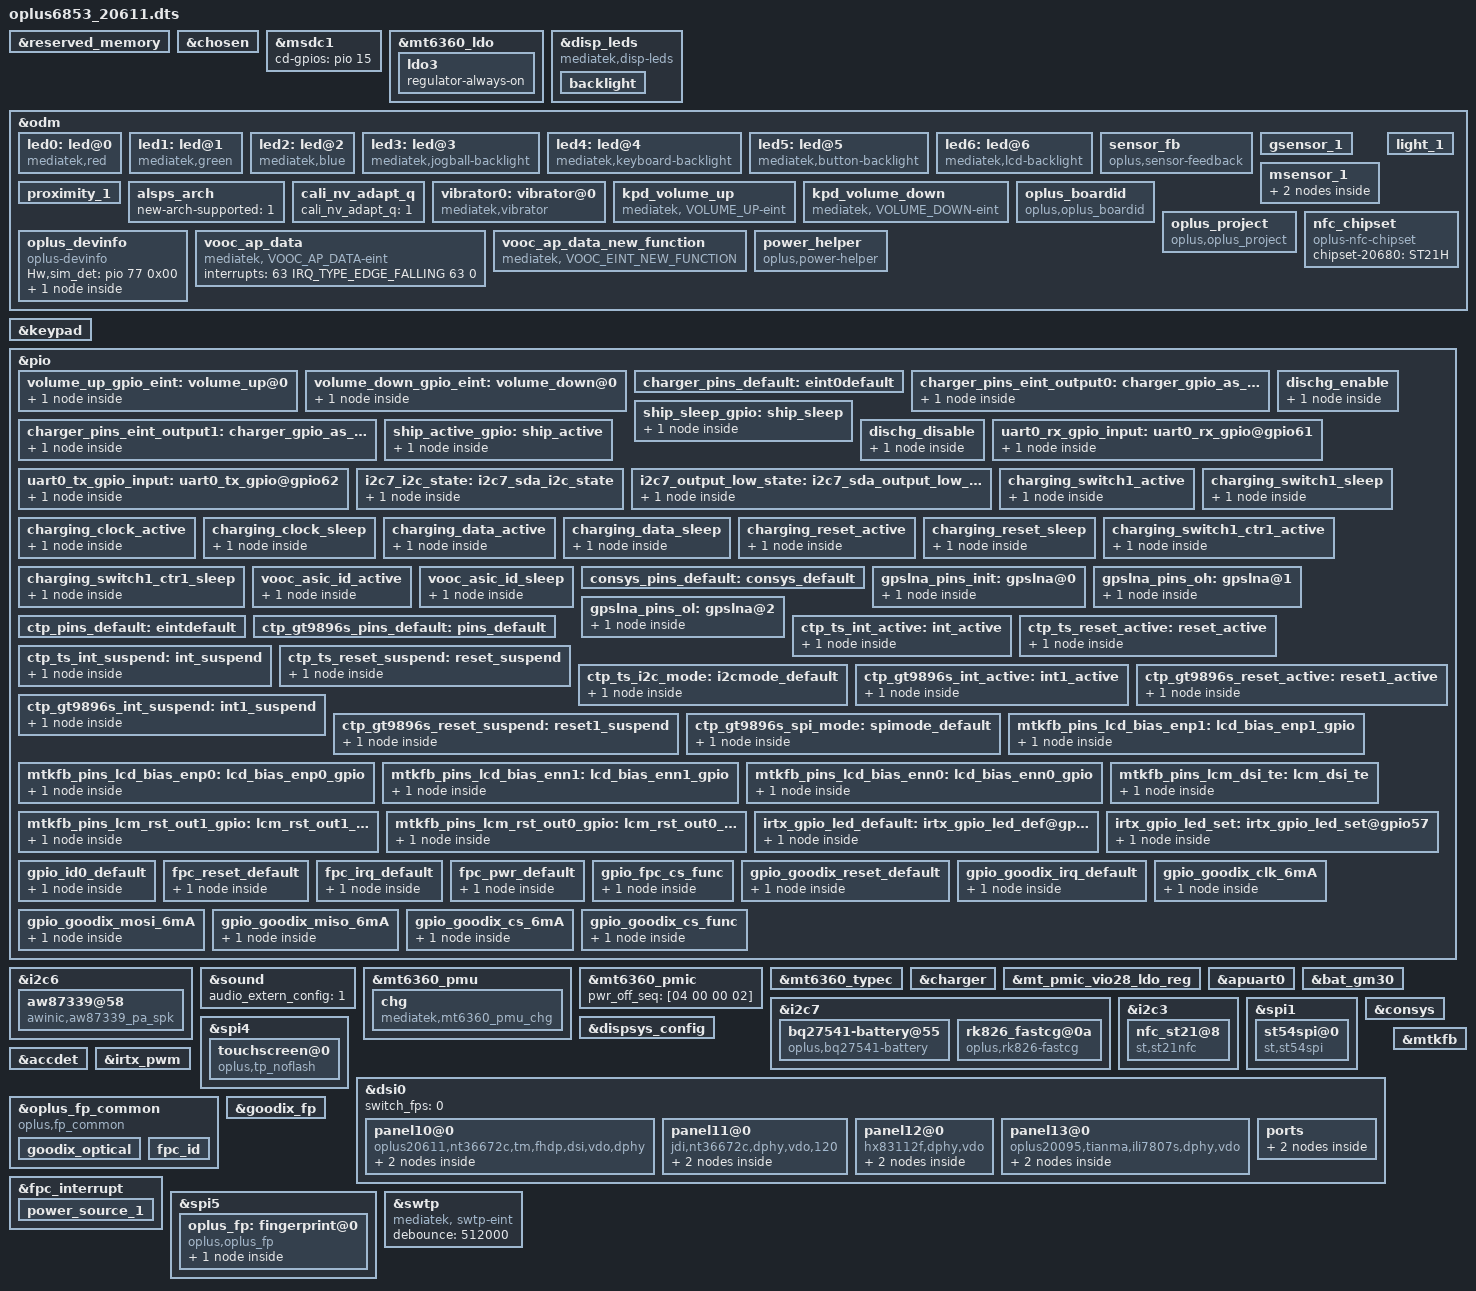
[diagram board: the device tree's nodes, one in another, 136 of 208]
/*
 * Mediatek's mt6853 SoC device tree source
 *
 * Copyright (C) 2016 MediaTek Inc.
 *
 * This program is free software; you can redistribute it and/or modify
 * it under the terms of the GNU General Public License version 2 as
 * published by the Free Software Foundation.
 *
 * This program is distributed in the hope that it will be useful,
 * but WITHOUT ANY WARRANTY; without even the implied warranty of
 * MERCHANTABILITY or FITNESS FOR A PARTICULAR PURPOSE.
 * See http://www.gnu.org/licenses/gpl-2.0.html for more details.
 */
/dts-v1/;
/plugin/;
#include <dt-bindings/interrupt-controller/irq.h>
#include <dt-bindings/interrupt-controller/arm-gic.h>
#include <dt-bindings/pinctrl/mt6853-pinfunc.h>

&reserved_memory {
};

/* chosen */
&chosen {

	atag,videolfb-fb_base_l = <0x7e605000>;
	atag,videolfb-fb_base_h = <0x0>;
	atag,videolfb-islcmfound = <1>;
	atag,videolfb-islcm_inited = <0>;
	atag,videolfb-fps= <6000>;
	atag,videolfb-vramSize= <0x1be0000>;
	atag,videolfb-lcmname=
		"nt35595_fhd_dsi_cmd_truly_nt50358_drv";
};
&msdc1 {
	cd-gpios = <&pio 15 0>;
	status = "okay";
};
&mt6360_ldo {
	sdcard_det_en = <1>;
	sdcard_hlact = <0>;
};

&disp_leds {
	compatible = "mediatek,disp-leds";

	backlight {
		label = "lcd-backlight";
		max-brightness = <4095>;
		led-bits = <12>;
		trans-bits = <12>;
		default-state = "on";
	};
};

&odm {
	led0:led@0 {
		compatible = "mediatek,red";
		led_mode = <0>;
		data = <1>;
		pwm_config = <0 0 0 0 0>;
	};
	led1:led@1 {
		compatible = "mediatek,green";
		led_mode = <0>;
		data = <1>;
		pwm_config = <0 0 0 0 0>;
	};
	led2:led@2 {
		compatible = "mediatek,blue";
		led_mode = <0>;
		data = <1>;
		pwm_config = <0 0 0 0 0>;
	};
	led3:led@3 {
		compatible = "mediatek,jogball-backlight";
		led_mode = <0>;
		data = <1>;
		pwm_config = <0 0 0 0 0>;
	};
	led4:led@4 {
		compatible = "mediatek,keyboard-backlight";
		led_mode = <0>;
		data = <1>;
		pwm_config = <0 0 0 0 0>;
	};
	led5:led@5 {
		compatible = "mediatek,button-backlight";
		led_mode = <0>;
		data = <1>;
		pwm_config = <0 0 0 0 0>;
	};
	led6:led@6 {
		compatible = "mediatek,lcd-backlight";
		led_mode = <4>;
		data = <1>;
		pwm_config = <0 1 0 0 0>;
	};

	sensor_fb: sensor_fb {
		compatible = "oplus,sensor-feedback";
	};

		/*
	enum {
		LIS3DH,
		LSM6DS3,
		BMI160,
		LIS2HH12,
		LSM6DSM,
		BMI2XY,
	};
	*/

	gsensor_1: gsensor_1 {
		status = "okay";
		sensor_name = <4>;//LSM6DSM
		i2c_num = <2>;
		i2c_addr = <0>;
		direction = <3>;
		eint_num = <3>;
		gyro_cali_version= <2>;
		acc_cali_range= <200 200 200>; //250mg
		step_count_7_en = <0>;
		config_miso = <0>;
		correct_y_bias = <0>;
                cali_nv_adapt_q_flag = <1>; // just for oplus MTK5G q projects
	};
	/*
	enum {
		AKM09911,
		MMC3530,
		MMC5603,
		MXG4300,
	};
	*/
	msensor_1: msensor_1 {
		status = "okay";
		sensor_name = <2>;//MMC5603
		i2c_num = <0>;
		i2c_addr = <48>;
		direction = <2>;
		eint_num = <0>;
 		parameter-number= <18>;
                para_num = <2>;
		mag_para_1 {
			match_projects = <20611 20610 20613 20686>;
			soft-mag-parameter = <9998 0 109 1 199 0 107 0 8922 0 268 0 58 1 468 0 10857 0>;
		};
		mag_para_2 {
			match_projects = <20680>;
			soft-mag-parameter = <15500 0 780 0 73 0 1639 0 9540 0 436 0 2000 0 5010 1 12560 0>;
		};
	};
	/*
	enum {
		TMD2725,
		APSD9922,
		STK3335,
		STK3331,
		STK2232,
		TCS3701,
		STK32600,
		TCS3408,
		STK33502,
	};
	*/
	proximity_1: proximity_1 {
		status = "okay";
		sensor_name = <7>;//STK33502
		i2c_num = <0>;
		i2c_addr = <70>;
		direction = <4>;
		eint_num = <11>;
		low_step = <300>;
		high_step = <400>;
		low_limit = <400>;
		high_limit = <600>;
		dirty_low_step = <100>;
		dirty_high_step = <150>;
		ps_dirty_limit = <1023>;
		ps_ir_limit = <500>;
		ps_adjust_min = <0>;
		ps_adjust_max = <600>;
		sampling_count = <5>;
		step_max = <400>;
		step_min = <100>;
		step_div = <1500>;
		anti_shake_delta = <80>;
		dynamic_cali_max = <2000>;
		raw2offset_radio = <1000>;
		offset_max = <60000>;
		offset_range_min = <0>;
		offset_range_max = <65534>;
		force_cali_limit = <2000>;
		cali_jitter_limit = <30>;
		cal_offset_margin = <3000>;
	};
	light_1: light_1 {
		status = "okay";
		sensor_name = <7>;//STK33502
		i2c_num = <0>;
		i2c_addr = <70>;
		direction = <4>;
		eint_num = <11>;
		als_buffer_length =<4>;
		als_type = <1>;//<1-normal;2-under screen;3-normal needed compensation>
		als_ratio = <170>;
		device_name = "stk33502";
		coefficient_mode = <1>;
	};
	alsps_arch: alsps_arch {
		status = "okay";
		new-arch-supported = <1>;
	};
	cali_nv_adapt_q: cali_nv_adapt_q {
		status = "okay";
		cali_nv_adapt_q = <1>;
	};
	vibrator0:vibrator@0 {
		compatible = "mediatek,vibrator";
		vib_timer = <30>;
		vib_limit = <0>;
		vib_vol= <11>;
	};

	kpd_volume_up:kpd_volume_up {
		compatible = "mediatek, VOLUME_UP-eint";
		interrupt-parent = <&pio>;
		interrupts = <1 IRQ_TYPE_EDGE_FALLING 1 0>;
		debounce = <32000>;
		status = "okay";
	};

	kpd_volume_down:kpd_volume_down {
		compatible = "mediatek, VOLUME_DOWN-eint";
		interrupt-parent = <&pio>;
		interrupts = <80 IRQ_TYPE_EDGE_FALLING 80 0>;
		debounce = <32000>;
		status = "okay";
	};
	oplus_boardid:oplus_boardid {
		compatible = "oplus,oplus_boardid";
		oplus_boardid,dtsino="20611";//only one u32
		oplus_boardid,pcbmask="0xffff";//all mask 0xffff
	};

	oplus_project:oplus_project {
		compatible = "oplus,oplus_project";
	};
	oplus_devinfo:oplus_devinfo {
		compatible = "oplus-devinfo";

		main-sub {
			compatible = "hw-match, main-sub";
			aboard-patterns = <0 0 0 0 0 0>;
			/*main board*/
			match-projects = <20610 20611 20613 20680 20686 20095>;
		};
	};

	vooc_ap_data:vooc_ap_data {
		compatible = "mediatek, VOOC_AP_DATA-eint";
		interrupts = <63 IRQ_TYPE_EDGE_FALLING 63 0>;
	};
	vooc_ap_data_new_function:vooc_ap_data_new_function {
		compatible = "mediatek, VOOC_EINT_NEW_FUNCTION";
	};

	//#ifdef OPLUS_FEATURE_NFC_CONSOFT
        nfc_chipset:nfc_chipset {
                compatible = "oplus-nfc-chipset";
                chipset-20680 = "ST21H";
        };
	//#endif /* OPLUS_FEATURE_NFC_CONSOFT */
};

&oplus_devinfo {
	Hw,sim_det = <&pio 77 0x00>;
};

&keypad {
	keypad,volume-up	= <&pio 1 0x00>;
	keypad,volume-down	= <&pio 80 0x00>;
	pinctrl-names = "volume_up_as_int", "volume_down_as_int";
	pinctrl-0 = <&volume_up_gpio_eint>;
	pinctrl-1 = <&volume_down_gpio_eint>;
	status = "okay";
};
&pio {
	volume_up_gpio_eint:volume_up@0{
		pins_cmd_dat {
			pinmux = <PINMUX_GPIO1__FUNC_GPIO1>;
			slew-rate = <0>;  /*direction 0:in, 1:out*/
			input-enable;
		};
	};

	volume_down_gpio_eint:volume_down@0{
		pins_cmd_dat {
			pinmux = <PINMUX_GPIO80__FUNC_GPIO80>;
			slew-rate = <0>;  /*direction 0:in, 1:out*/
			input-enable;
		};
	};
};

&i2c6 {
    #address-cells = <1>;
    #size-cells = <0>;

    aw87339@58 {
        compatible = "awinic,aw87339_pa_spk";
        reg = <0x58>;
        //reset-gpio = <&tlmm 114 0x01>;
        reset-gpio = <&pio 139 0>;
        status = "okay";
    };
};

&sound {
	/* this dtsi config for product's special config, AudioHal read ctl 'OPLUS_AUDIO_EXTERN_CONFIG'
	 * get the values*
	 * 1st value --> PA type: 0:NXP Pa, 1:Awinic Pa */
	audio_extern_config = <1>;
};


&oplus_devinfo {
	Hw,sim_det = <&pio 77 0x00>;
};

/* Charging Start */

&mt6360_pmu {
	mt6360,intr_gpio_num = <10>; /* direct defined GPIO num */
	mt6360,intr_gpio = <&pio 10 0x0>;
	disable_lpsd = <1>;
};

&mt6360_pmic {
	pwr_off_seq = [04 00 00 02];
};

&mt6360_typec {
	mt6360pd,intr_gpio_num = <9>; /* direct defined GPIO num */
	mt6360pd,intr_gpio = <&pio 9 0x0>;
	//mt6360pd,pcb_gpio = <&pio 57 0x0>;
	//mt6360pd,pcb_gpio_num = <57>;
};

&mt6360_pmu {
	chg {
		compatible = "mediatek,mt6360_pmu_chg";
		interrupt-parent = <&mt6360_pmu>;
		interrupts = <4 0>, <6 0>, <7 0>, <9 0>,
				<12 0>, <13 0>, <14 0>, <15 0>,
				<27 0>, <29 0>, <30 0>, <32 0>,
				<35 0>, <40 0>, <48 0>, <60 0>,
				<53 0>;
		interrupt-names = "chg_treg_evt", "chg_mivr_evt",
				"pwr_rdy_evt", "chg_batsysuv_evt",
				"chg_vsysuv_evt", "chg_vsysov_evt",
				"chg_vbatov_evt", "chg_vbusov_evt",
				"chg_tmri", "chg_adpbadi",
				"chg_rvpi",  "chg_aiccmeasl",
				"wdtmri", "pumpx_donei",
				"attachi", "chrdet_ext_evt",
				"hvdcp_det";
		io-channels = <&adc 0>, <&adc 1>, <&adc 3>, <&adc 4>,
				<&adc 5>, <&adc 6>, <&adc 8>, <&adc 10>;
		io-channel-names = "USBID", "VBUSDIV5", "VSYS", "VBAT",
				"IBUS", "IBAT", "TEMP_JC", "TS";
		chg_name = "primary_chg";
		ichg = <2000000>;               /* uA */
		aicr = <500000>;                /* uA */
		mivr = <4400000>;               /* uV */
		cv = <4350000>;                 /* uA */
		ieoc = <150000>;                /* uA */
		safety_timer = <12>;            /* hour */
		ircmp_resistor = <25000>;       /* uohm */
		ircmp_vclamp = <32000>;         /* uV */
		en_te = <1>;
		en_wdt = <1>;
		aicc_once = <1>;
		post_aicc = <1>;
		batoc_notify = <0>;
	};
};
&mt6360_ldo{
	ldo3{
		regulator-always-on;
	};
};
//#ifdef OPLUS_FEATURE_SDCARD
&mt6360_ldo {
	ldo5_ctrls = [00 80 01 2d a4];
};
//#endif OPLUS_FEATURE_SDCARD
&charger {
	io-channels = <&auxadc 3>,
		<&auxadc 4>,
		<&auxadc 5>;
	io-channel-names = "auxadc3-chargeric_temp",
		"auxadc4-usb_temp_v_l",
		"auxadc5-usb_temp_v_r";

	pinctrl-names = "default", "charger_gpio_as_output_low", "charger_gpio_as_output_high", "ship_sleep", "ship_active", 
		"dischg_enable", "dischg_disable";
		//"ccdetect_active","ccdetect_sleep";
	pinctrl-0 = <&charger_pins_default>;
	pinctrl-1 = <&charger_pins_eint_output0>;//USB_ON
	pinctrl-2 = <&charger_pins_eint_output1>;//USB_ON
	pinctrl-3 = <&ship_sleep_gpio>;
	pinctrl-4 = <&ship_active_gpio>;
	pinctrl-5 = <&dischg_enable>;
	pinctrl-6 = <&dischg_disable>;
	//pinctrl-5 = <&shortc_active_gpio>;
	//pinctrl-7 = <&ccdetect_active>;
	//pinctrl-8 = <&ccdetect_sleep>;

	qcom,input_current_charger_ma = <2300>;
	qcom,pd_input_current_charger_ma = <3300>;
	qcom,qc_input_current_charger_ma = <2000>;
	qcom,input_current_usb_ma = <500>;

	qcom,input_current_cdp_ma = <1500>;
	qcom,input_current_led_ma = <1200>;
	qcom,input_current_led_ma_high = <1200>;
	qcom,input_current_led_ma_warm = <1500>;
	qcom,input_current_led_ma_normal = <2300>;
	qcom,led_warm_bat_decidegc = <350>;
	qcom,led_high_bat_decidegc = <370>;

	qcom,input_current_camera_ma = <1200>;

	qcom,input_current_vooc_led_ma_high = <1200>;
	qcom,input_current_vooc_led_ma_warm = <1800>;
	qcom,input_current_vooc_led_ma_normal = <3600>;
	qcom,input_current_vooc_ma_normal = <3600>;
	qcom,vooc_temp_bat_normal_decidegc = <350>;
	qcom,input_current_vooc_ma_warm = <3200>;
	qcom,vooc_temp_bat_warm_decidegc = <370>;
	qcom,input_current_vooc_ma_high = <2200>;
	qcom,vooc_temp_bat_hot_decidegc = <440>;

	qcom,charger_current_vooc_ma_normal = <1800>;

	qcom,input_current_calling_ma = <1500>;

	qcom,overtemp_bat_decidegc = <350>;
	qcom,iterm_disabled = <0>;
	qcom,iterm_ma = <255>;
	qcom,recharge-mv = <100>;
	qcom,batt_capacity_mah = <5000>;/*typical capacity*/

	qcom,removed_bat_decidegc = <190>;  /*<-19C*/

	qcom,cold_bat_decidegc = <20>;  /*-2C~0C*/
	qcom,temp_cold_vfloat_mv = <3980>;
	qcom,temp_cold_fastchg_current_ma = <350>;

	qcom,little_cold_bat_decidegc = <0>;    /*0C~5C*/
	qcom,temp_little_cold_vfloat_mv = <4435>;
	qcom,temp_little_cold_fastchg_current_ma_high = <2300>;
	qcom,temp_little_cold_fastchg_current_ma_low = <1400>;
	qcom,temp_little_cold_fastchg_current_ma = <1400>;
	qcom,pd_temp_little_cold_fastchg_current_ma_high = <2300>;
	qcom,pd_temp_little_cold_fastchg_current_ma_low = <1400>;
	qcom,qc_temp_little_cold_fastchg_current_ma_high = <2000>;
	qcom,qc_temp_little_cold_fastchg_current_ma_low = <1400>;

	qcom,cool_bat_decidegc = <50>;  /*5C~12C*/
	qcom,temp_cool_vfloat_mv = <4435>;
	qcom,temp_cool_fastchg_current_ma_high = <2300>;
	qcom,temp_cool_fastchg_current_ma_low = <2300>;
	qcom,pd_temp_cool_fastchg_current_ma_high = <2300>;
	qcom,pd_temp_cool_fastchg_current_ma_low = <2300>;
	qcom,qc_temp_cool_fastchg_current_ma_high = <2000>;
	qcom,qc_temp_cool_fastchg_current_ma_low = <2000>;

	qcom,little_cool_bat_decidegc = <120>;  /*12C~16C*/
	qcom,temp_little_cool_vfloat_mv = <4435>;
	qcom,temp_little_cool_fastchg_current_ma = <2300>;
	qcom,pd_temp_little_cool_fastchg_current_ma = <3300>;
	qcom,qc_temp_little_cool_fastchg_current_ma = <2000>;

	qcom,normal_bat_decidegc = <160>;       /*16C~44C*/
	qcom,temp_normal_fastchg_current_ma = <2300>;
	qcom,temp_normal_vfloat_mv = <4435>;
	qcom,pd_temp_normal_fastchg_current_ma = <3300>;
	qcom,qc_temp_normal_fastchg_current_ma = <2000>;

	qcom,warm_bat_decidegc = <450>;         /*45C~53C*/ /*8pin Bat Vooc project need add 3 degree C*/
	qcom,temp_warm_vfloat_mv = <4130>;
	qcom,temp_warm_fastchg_current_ma = <1400>;
	qcom,pd_temp_warm_fastchg_current_ma = <1400>;
	qcom,qc_temp_warm_fastchg_current_ma = <1400>;
	qcom,temp_warm_fastchg_current_ma_led_on = <500>;

	qcom,hot_bat_decidegc = <530>;

	qcom,non_standard_vfloat_mv = <3980>;
	qcom,non_standard_fastchg_current_ma = <512>;

	qcom,short_c_bat_cv_mv = <4330>;
	qcom,short_c_bat_vfloat_mv = <3800>;
	qcom,short_c_bat_fastchg_current_ma = <512>;

	qcom,cold_vfloat_sw_limit = <3930>;
	qcom,little_cold_vfloat_sw_limit = <4385>;
	qcom,cool_vfloat_sw_limit = <4385>;
	qcom,little_cool_vfloat_sw_limit = <4385>;
	qcom,normal_vfloat_sw_limit = <4385>;
	qcom,warm_vfloat_sw_limit = <4080>;
	qcom,non_standard_vfloat_sw_limit = <3930>;
	qcom,short_c_bat_vfloat_sw_limit = <3750>;

	qcom,max_chg_time_sec = <72000>;
	qcom,charger_hv_thr = <5800>;
	qcom,charger_recv_thr = <5500>;
	qcom,charger_lv_thr = <3400>;
	qcom,vbatt_full_thr = <4400>;
	qcom,vbatt_hv_thr = <4550>;
	qcom,vfloat_step_mv = <8>;
	qcom,non_standard_vfloat_over_sw_limit = <3990>;
	qcom,cold_vfloat_over_sw_limit = <3990>;
	qcom,little_cold_vfloat_over_sw_limit = <4445>;
	qcom,cool_vfloat_over_sw_limit = <4445>;
	qcom,little_cool_vfloat_over_sw_limit = <4445>;
	qcom,normal_vfloat_over_sw_limit = <4445>;
	qcom,warm_vfloat_over_sw_limit = <4140>;

	qcom,vbatt_power_off = <3300>;
	qcom,vbatt_soc_1 = <3410>;
	qcom,vooc_project = <1>;
	qcom,vbatt_num = <1>;
	qcom,normal_vterm_hw_inc = <18>;
	qcom,non_normal_vterm_hw_inc = <18>;
	qcom,new_ui_warning_support;
	qcom,ffc_support;
	qcom,ff1_normal_fastchg_ma = <1500>;
	qcom,ff1_exit_step_ma = <550>;

	qcom,ff1_warm_fastchg_ma = <1500>;
	qcom,ff1_warm_exit_step_ma = <500>;

	qcom,ffc2_normal_fastchg_ma = <1200>;/*12C~35c*/
	qcom,ffc2_exit_step_ma = <250>;

	qcom,ffc2_temp_low_decidegc = <120>;
	qcom,ffc2_temp_warm_decidegc = <350>;

	qcom,ffc2_warm_fastchg_ma = <1250>;/*35C~40c*/
	qcom,ffc2_warm_exit_step_ma = <250>;/*35C~40c*/

	qcom,ffc2_temp_high_decidegc = <400>;

	qcom,ffc_normal_vfloat_sw_limit = <4475>;
	qcom,ffc_warm_vfloat_sw_limit = <4475>;

	qcom,ffc2_normal_vfloat_sw_limit = <4475>;
	qcom,ffc2_warm_vfloat_sw_limit = <4475>;

	qcom,ffc_temp_normal_vfloat_mv = <4550>;
	qcom,ffc1_temp_normal_vfloat_mv = <4550>;
	qcom,ffc2_temp_normal_vfloat_mv = <4550>;
	qcom,ffc_normal_vfloat_over_sw_limit = <4550>;
	qcom,ffc1_normal_vfloat_over_sw_limit = <4550>;
	qcom,ffc2_normal_vfloat_over_sw_limit = <4550>;


	qcom,default_iterm_ma = <255>;
	qcom,default_temp_normal_fastchg_current_ma = <2200>;
	qcom,default_normal_vfloat_sw_limit = <4385>;
	qcom,default_temp_normal_vfloat_mv = <4435>;
	qcom,default_normal_vfloat_over_sw_limit = <4445>;

	qcom,default_temp_little_cool_fastchg_current_ma = <2200>;
	qcom,default_little_cool_vfloat_sw_limit = <4385>;
	qcom,default_temp_little_cool_vfloat_mv = <4435>;
	qcom,default_little_cool_vfloat_over_sw_limit = <4445>;

	qcom,smart_charge_version = <0>;

	qcom,vooc_show_ui_soc_decimal;
	qcom,ui_soc_decimal_speedmin = <20>;//2A
	qcom,check_batt_full_by_sw;
	qcom,external_gauge;
	qcom,chg_ctrl_by_calling;
	qcom,chg_ctrl_by_lcd;
	//qcom,chg_ctrl_by_vooc;
	qcom,chg_ctrl_by_camera;
	qcom,chargerid_support;
	qcom,sw_vfloat_over_protect_enable;
	qcom,lpd-disable;
	//for PD9V or QC9V
	qcom,vbatt_pdqc_to_5v_thr = <4180>;

	//GPIO config:
	qcom,chargerid_switch-gpio = <&pio 40 0x00>;//USB_ON
	qcom,ship-gpio = <&pio 34 0x00>;
	qcom,dischg-gpio = <&pio 39 0x00>;//VBUS_SHORT
	//qcom,shortc-gpio = <&pio 121 0x00>;
	//qcom,ccdetect-gpio = <&pio 5 0x00>;//USB_ACC_INT
};
&mt_pmic_vio28_ldo_reg {
	regulator-name = "vio28";
	regulator-min-microvolt = <3000000>;
	regulator-max-microvolt = <3000000>;
	regulator-enable-ramp-delay = <240>;
};
//#endif /* VENDOR_EDIT */

&pio {
	charger_pins_default: eint0default {
	};

	charger_pins_eint_output0: charger_gpio_as_output_low {
		pins_cmd_dat {
			pinmux = <PINMUX_GPIO40__FUNC_GPIO40>;
			slew-rate = <1>;
			output-low;
		};
	};

	charger_pins_eint_output1: charger_gpio_as_output_high {
		pins_cmd_dat {
			pinmux = <PINMUX_GPIO40__FUNC_GPIO40>;
			slew-rate = <1>;
			output-high;
		};
	};

	ship_sleep_gpio: ship_sleep {
		pins_cmd_dat {
			pinmux = <PINMUX_GPIO34__FUNC_GPIO34>;
			slew-rate = <1>;
			output-low;
		};
	};

	ship_active_gpio: ship_active {
		pins_cmd_dat {
			pinmux = <PINMUX_GPIO34__FUNC_GPIO34>;
			slew-rate = <1>;
			output-high;
		};
	};
	dischg_enable: dischg_enable {
		pins_cmd_dat {
			pinmux = <PINMUX_GPIO39__FUNC_GPIO39>;
			slew-rate = <1>;//0:input direction 1:output direction
			bias-pull-up = <00>;
			output-high;
		};
	};

	dischg_disable: dischg_disable {
		pins_cmd_dat {
			pinmux = <PINMUX_GPIO39__FUNC_GPIO39>;
			slew-rate = <1>;
			bias-pull-down = <00>;
			output-low;
		};
	};
};

&apuart0 {
	pinctrl-names = "uart0_rx_gpio",
			"uart0_tx_gpio";
	pinctrl-0 = <&uart0_rx_gpio_input>;
	pinctrl-1 = <&uart0_tx_gpio_input>;
	status = "okay";
};

&pio {
	uart0_rx_gpio_input:uart0_rx_gpio@gpio61 {
		pins_cmd_dat {
			pinmux = <PINMUX_GPIO61__FUNC_GPIO61>;
			input-enable;
			slew-rate = <0>;
			//bias-disable;
			bias-pull-down = <00>;
		};
	};
	uart0_tx_gpio_input:uart0_tx_gpio@gpio62 {
		pins_cmd_dat {
			pinmux = <PINMUX_GPIO62__FUNC_GPIO62>;
			input-enable;
			slew-rate = <0>;
			//bias-disable;
			bias-pull-down = <00>;
		};
	};
};

//#endif /* VENDOR_EDIT */




&bat_gm30 {
	DISABLE_MTKBATTERY = <(1)>;
	enable_tmp_intr_suspend = <(1)>;
};

&i2c7 {
       pinctrl-names = "i2c-state", "output-low-state";

       pinctrl-0 = <&i2c7_i2c_state>;
       pinctrl-1 = <&i2c7_output_low_state>;
};
&pio {
       i2c7_i2c_state: i2c7_sda_i2c_state {
                pins_cmd_dat {
                          pinmux = <PINMUX_GPIO112__FUNC_SDA7>;
                          slew-rate = <0>;
                          bias-pull-up = <11>;
                };
       };
       i2c7_output_low_state: i2c7_sda_output_low_state {
                pins_cmd_dat {
                          pinmux = <PINMUX_GPIO112__FUNC_GPIO112>;
                          slew-rate = <1>;
                          output-low;
                };
       };
};
&i2c7 {
	status = "okay";
	//clock-frequency = <100000>;
	bq27541-battery@55 {
		status = "okay";
		compatible = "oplus,bq27541-battery";
		reg = <0x55 0>;
		qcom,modify-soc-smooth;
		//qcom,batt_bq28z610;
                //qcom,bq28z610_need_balancing;
	};


	rk826_fastcg@0a{
		status = "okay";
		compatible = "oplus,rk826-fastcg";
		reg = <0x0a 0>;
		qcom,vooc-low-temp = <50>;
		qcom,oplus_batt_4400mv;
		qcom,vooc_fw_update_newmethod;
		qcom,vooc-high-temp = <430>;
		qcom,vooc-low-soc = <1>;
		qcom,vooc-high-soc = <85>;
		qcom,vooc-fw-type = <7>;

		qcom,vooc_cool_bat_volt = <3450>;
		qcom,vooc_little_cool_bat_volt = <3400>;
		qcom,vooc_normal_bat_volt = <3350>;
		qcom,vooc_warm_bat_volt = <3300>;

		qcom,vooc_cool_bat_suspend_volt = <3450>;
		qcom,vooc_little_cool_bat_suspend_volt = <3400>;
		qcom,vooc_normal_bat_suspend_volt = <3350>;
		qcom,vooc_warm_bat_suspend_volt = <3300>;

		qcom,vooc_multistep_adjust_current_support;
		qcom,vooc_multistep_initial_batt_temp = <1000>;
		qcom,vooc_strategy_normal_current = <0x06>;

		qcom,vooc-normal-to-little-cool-current = <0x04>;
		//qcom,vooc_batt_over_high_temp = <440>;//exit move to fastchg bin
		//qcom,vooc_batt_over_low_temp = <45>;//exit move to fastchg bin
		qcom,vooc_over_high_or_low_current = <0x02>;

		qcom,vooc_strategy1_batt_high_temp0 = <410>;
		qcom,vooc_strategy1_batt_high_temp1 = <425>;
		qcom,vooc_strategy1_batt_high_temp2 = <435>;
		qcom,vooc_strategy1_batt_low_temp2 = <430>;
		qcom,vooc_strategy1_batt_low_temp1 = <410>;
		qcom,vooc_strategy1_batt_low_temp0 = <390>;

		qcom,vooc_strategy1_high_current0 = <0x04>;//4A
		qcom,vooc_strategy1_high_current1 = <0x03>;//3A
		qcom,vooc_strategy1_high_current2 = <0x02>;//2A
		qcom,vooc_strategy1_low_current2 = <0x03>;//3A
		qcom,vooc_strategy1_low_current1 = <0x05>;//5A
		qcom,vooc_strategy1_low_current0 = <0x06>;//6A

		qcom,vooc_strategy2_batt_up_temp1 = <375>;
		qcom,vooc_strategy2_batt_up_down_temp2 = <380>;
		qcom,vooc_strategy2_batt_up_temp3 = <390>;
		qcom,vooc_strategy2_batt_up_down_temp4 = <400>;
		qcom,vooc_strategy2_batt_up_temp5 = <410>;
		qcom,vooc_strategy2_batt_up_temp6 = <415>;
		qcom,vooc_strategy2_high0_current = <0x06>;
		qcom,vooc_strategy2_high1_current = <0x06>;
		qcom,vooc_strategy2_high2_current = <0x06>;
		qcom,vooc_strategy2_high3_current = <0x06>;
		pinctrl-names = "switch1_act_switch2_act", "switch1_sleep_switch2_sleep",
						"switch1_act_switch3_act", "switch1_sleep_switch3_sleep",
						"switch1_act_switch2_sleep", "switch1_sleep_switch2_act",
						"clock_active","clock_sleep",
						"data_active","data_sleep",
						"reset_active","reset_sleep",
						"charging_switch1_ctr1_active","charging_switch1_ctr1_sleep",
						"vooc_asic_id_active","vooc_asic_id_sleep";
		pinctrl-0 = <&charging_switch1_active>;//USB_SW_CTRL1
		pinctrl-1 = <&charging_switch1_sleep>;//USB_SW_CTRL1
		pinctrl-2 = <&charging_switch1_active>;//USB_SW_CTRL1
		pinctrl-3 = <&charging_switch1_sleep>;//USB_SW_CTRL1
		pinctrl-4 = <&charging_switch1_active>;//USB_SW_CTRL1
		pinctrl-5 = <&charging_switch1_sleep>;//USB_SW_CTRL1
		pinctrl-6 = <&charging_clock_active>;//AP_CLK
		pinctrl-7 = <&charging_clock_sleep>;//AP_CLK
		pinctrl-8 = <&charging_data_active>;//AP_DATA
		pinctrl-9 = <&charging_data_sleep>;//AP_DATA
		pinctrl-10 = <&charging_reset_active>;//MCU_EN
		pinctrl-11 = <&charging_reset_sleep>;//MCU_EN
		pinctrl-12 = <&charging_switch1_ctr1_active>;//USB_SW_CTRL2
		pinctrl-13 = <&charging_switch1_ctr1_sleep>;//USB_SW_CTRL2
		pinctrl-14 = <&vooc_asic_id_active>;
		pinctrl-15 = <&vooc_asic_id_sleep>;
		qcom,charging_switch1-gpio 		= <&pio 32 0x00>;//USB_SW_CTRL1
		qcom,charging_switch1_ctr1-gpio 	= <&pio 76 0x00>;//USB_SW_CTRL2//must set a gpio


		qcom,charging_reset-gpio 			= <&pio 132 0x00>;//MCU_EN
		qcom,charging_clock-gpio 			= <&pio 64 0x00>;//AP_CLK
		qcom,charging_data-gpio 			= <&pio 63 0x00>;//AP_DATA
		qcom,vooc_asic_id-gpio				= <&pio 134 0x00>;
	};
};

&pio {
	charging_switch1_active: charging_switch1_active {
		pins_cmd_dat {
			pinmux = <PINMUX_GPIO32__FUNC_GPIO32>;
			slew-rate = <1>;
			output-high;
		};
	};

	charging_switch1_sleep: charging_switch1_sleep {
		pins_cmd_dat {
			pinmux = <PINMUX_GPIO32__FUNC_GPIO32>;
			slew-rate = <1>;
			output-low;
		};
	};

	charging_clock_active: charging_clock_active {
		pins_cmd_dat {
			pinmux = <PINMUX_GPIO64__FUNC_GPIO64>;
			slew-rate = <0>;
			bias-pull-up;
		};
	};

	charging_clock_sleep: charging_clock_sleep {
		pins_cmd_dat {
			pinmux = <PINMUX_GPIO64__FUNC_GPIO64>;
			slew-rate = <0>;
			bias-pull-down;
		};
	};

	charging_data_active: charging_data_active {
		pins_cmd_dat {
			pinmux = <PINMUX_GPIO63__FUNC_GPIO63>;
			slew-rate = <0>;
			bias-pull-down;
		};
	};

	charging_data_sleep: charging_data_sleep {
		pins_cmd_dat {
			pinmux = <PINMUX_GPIO63__FUNC_GPIO63>;
			slew-rate = <0>;
			bias-pull-down;
		};
	};

	charging_reset_active: charging_reset_active {
		pins_cmd_dat {
			pinmux = <PINMUX_GPIO132__FUNC_GPIO132>;
			slew-rate = <1>;
			output-high;
		};
	};

	charging_reset_sleep: charging_reset_sleep {
		pins_cmd_dat {
			pinmux = <PINMUX_GPIO132__FUNC_GPIO132>;
			slew-rate = <1>;
			output-low;
		};
	};

	charging_switch1_ctr1_active: charging_switch1_ctr1_active {
		pins_cmd_dat {
			pinmux = <PINMUX_GPIO76__FUNC_GPIO76>;
			slew-rate = <1>;
			output-high;
		};
	};
	charging_switch1_ctr1_sleep: charging_switch1_ctr1_sleep {
		pins_cmd_dat {
			pinmux = <PINMUX_GPIO76__FUNC_GPIO76>;
			slew-rate = <1>;
			output-low;
		};
	};
	vooc_asic_id_active: vooc_asic_id_active {
		pins_cmd_dat {
			pinmux = <PINMUX_GPIO134__FUNC_GPIO134>;
			input-enable;
			slew-rate = <0>;
			bias-pull-up;
		};
	};
	vooc_asic_id_sleep: vooc_asic_id_sleep {
		pins_cmd_dat {
			pinmux = <PINMUX_GPIO134__FUNC_GPIO134>;
			input-enable;
			slew-rate = <0>;
			bias-pull-down;
		};
	};
};

//#ifdef OPLUS_BUG_COMPATIBILITY
//NFC bring up
&i2c3 {
       nfc_st21@8 {
               compatible = "st,st21nfc";
               reg = <0x8>;
               gpio-irq-std    = <&pio 5 0x0>;
               gpio-rst-std    = <&pio 11 0x0>;
               //gpio-pidle-std  = <&pio 16 0x0>;
               gpio-clkreq-std = <&pio 81 0x0>;
			   status = "okay";
       };
};
//#endif /*OPLUS_BUG_COMPATIBILITY*/

//NFC GPIO start
&spi1 {
	st54spi@0 {
		compatible = "st,st54spi";
		reg = <0>;
		spi-max-frequency = <1000000> ;
		gpio-power = <8>;
		gpio-power-std = <&pio 8 0x0>;
		status = "okay";
	};
};
//NFC GPIO end
//#endif /* VENDOR_EDIT */

/* CONSYS GPIO standardization */
&pio {
	consys_pins_default: consys_default {
	};
	gpslna_pins_init: gpslna@0 {
		pins_cmd_dat {
			pinmux = <PINMUX_GPIO87__FUNC_GPIO87>;
			output-low;
		};
	};
	gpslna_pins_oh: gpslna@1 {
		pins_cmd_dat {
			pinmux = <PINMUX_GPIO87__FUNC_GPS_L1_ELNA_EN>;
		};
	};
	gpslna_pins_ol: gpslna@2 {
		pins_cmd_dat {
			pinmux = <PINMUX_GPIO87__FUNC_GPIO87>;
			output-low;
		};
	};
};

&consys {
	pinctrl-names = "default", "gps_lna_state_init",
		"gps_lna_state_oh", "gps_lna_state_ol";
	pinctrl-0 = <&consys_pins_default>;
	pinctrl-1 = <&gpslna_pins_init>;
	pinctrl-2 = <&gpslna_pins_oh>;
	pinctrl-3 = <&gpslna_pins_ol>;
	status = "okay";
};
/* CONSYS end */

/* TOUCH start */
&spi4 {
	status = "okay";

	touchscreen@0 {
		compatible = "oplus,tp_noflash";
		reg = <0>; //Same as CS ID
		chip-name = "OPLUS_TP_NOFLASH";
		status = "ok";

		spi-max-frequency = <9600000>;
		interrupt-parent = <&pio>;
		interrupts = <14 IRQ_TYPE_EDGE_FALLING 14 0>;
		irq-gpio = <&pio 14 0x2002>;
		reset-gpio = <&pio 33 0>;

		platform_support_project = <20610 20613 20680 20686 20611 20095>;
		platform_support_project_dir = <20611 20611 20611 20611 20611 20095>;
		platform_support_project_commandline = "default_commandline","default_commandline","default_commandline","default_commandline","default_commandline","default_commandline";

		touchpanel,max-num-support = <10>;
		touchpanel,tx-rx-num = <16 36>;
		touchpanel,panel-coords = <1080 2400>;
		touchpanel,display-coords = <1080 2400>;
		touchpanel,touchmajor-limit = <0 54>;

		pinctrl-names = "default", "suspend";
		pinctrl-0 = <&ctp_gt9896s_int_active &ctp_gt9896s_reset_active &ctp_gt9896s_spi_mode>;
		pinctrl-1 = <&ctp_gt9896s_int_suspend &ctp_gt9896s_reset_suspend>;

		incell_screen;
		fw_edge_limit_support;
		black_gesture_support;
		charger_pump_support;
		headset_pump_support;
		esd_handle_support;
		black_gesture_test_support;
		game_switch_support;
		noflash_support;
		lcd_trigger_load_tp_fw_support;
		smart_gesture_support;
		pressure_report_support;
		fw_update_app_support;
		health_monitor_v2_support;
		//fw_update_in_probe_with_headfile;

		touchpanel,button-type = <4>;
	};
};

&pio {
	ctp_pins_default: eintdefault {
	};
	ctp_gt9896s_pins_default: pins_default {
	};
	ctp_ts_int_active: int_active {
		pins_cmd_dat {
			pinmux = <PINMUX_GPIO14__FUNC_GPIO14>;
			slew-rate = <0>;
			bias-pull-up = <11>;
		};
	};
	ctp_ts_reset_active: reset_active {
		pins_cmd_dat {
			pinmux = <PINMUX_GPIO43__FUNC_GPIO43>;
			slew-rate = <1>;
			output-high;
		};
	};
	ctp_ts_int_suspend: int_suspend {
		pins_cmd_dat {
			pinmux = <PINMUX_GPIO14__FUNC_GPIO14>;
			slew-rate = <1>;
			output-low;
		};
	};
	ctp_ts_reset_suspend: reset_suspend {
		pins_cmd_dat {
			pinmux = <PINMUX_GPIO43__FUNC_GPIO43>;
			slew-rate = <1>;
			output-low;
		};
	};
	ctp_ts_i2c_mode: i2cmode_default {
		pins_cmd_dat {
			pinmux = <PINMUX_GPIO97__FUNC_SCL0>,
				<PINMUX_GPIO98__FUNC_SDA0>;
		};
	};
	ctp_gt9896s_int_active: int1_active {
		pins_cmd_dat {
			pinmux = <PINMUX_GPIO14__FUNC_GPIO14>;
			slew-rate = <0>;
			bias-pull-up = <11>;
		};
	};
	ctp_gt9896s_reset_active: reset1_active {
		pins_cmd_dat {
			pinmux = <PINMUX_GPIO43__FUNC_GPIO43>;
			slew-rate = <1>;
			output-high;
		};
	};
	ctp_gt9896s_int_suspend: int1_suspend {
		pins_cmd_dat {
			pinmux = <PINMUX_GPIO14__FUNC_GPIO14>;
			slew-rate = <1>;
			output-low;
		};
	};
	ctp_gt9896s_reset_suspend: reset1_suspend {
		pins_cmd_dat {
			pinmux = <PINMUX_GPIO43__FUNC_GPIO43>;
			slew-rate = <1>;
			output-low;
		};
	};
	ctp_gt9896s_spi_mode: spimode_default {
		pins_cmd_dat {
			pinmux = <PINMUX_GPIO12__FUNC_SPI4_MI>,
				<PINMUX_GPIO13__FUNC_SPI4_MO>,
				<PINMUX_GPIO97__FUNC_SPI4_CLK>,
				<PINMUX_GPIO98__FUNC_SPI4_CSB>;
			drive-strength = <4>;
		};
	};
};
//#endif /* VENDOR_EDIT */  

/*
&sound {
	mediatek,speaker-codec {
		sound-dai = <&speaker_amp>;
	};
};

&i2c6 {
	speaker_amp: speaker_amp@34 {
		compatible = "mediatek,speaker_amp";
		#sound-dai-cells = <0>;
		reg = <0x34>;
		status = "okay";
	};
};
*/

#include "mediatek/cust_mt6853_camera_20611.dtsi"
#include <oplus6853_20611/cust.dtsi>
/* DISPSYS GPIO standardization */

#ifndef CONFIG_FPGA_EARLY_PORTING
&pio {
	mtkfb_pins_lcd_bias_enp1: lcd_bias_enp1_gpio {
		pins_cmd_dat {
			pinmux = <PINMUX_GPIO137__FUNC_GPIO137>;
			slew-rate = <1>;
			output-high;
		};
	};

	mtkfb_pins_lcd_bias_enp0: lcd_bias_enp0_gpio {
		pins_cmd_dat {
			pinmux = <PINMUX_GPIO137__FUNC_GPIO137>;
			slew-rate = <1>;
			output-low;
		};
	};

	mtkfb_pins_lcd_bias_enn1: lcd_bias_enn1_gpio {
		pins_cmd_dat {
			pinmux = <PINMUX_GPIO138__FUNC_GPIO138>;
			slew-rate = <1>;
			output-high;
		};
	};

	mtkfb_pins_lcd_bias_enn0: lcd_bias_enn0_gpio {
		pins_cmd_dat {
			pinmux = <PINMUX_GPIO138__FUNC_GPIO138>;
			slew-rate = <1>;
			output-low;
		};
	};

	mtkfb_pins_lcm_rst_out1_gpio: lcm_rst_out1_gpio {
		pins_cmd_dat {
			pinmux = <PINMUX_GPIO86__FUNC_GPIO86>;
			slew-rate = <1>;
			output-high;
		};
	};

	mtkfb_pins_lcm_rst_out0_gpio: lcm_rst_out0_gpio {
		pins_cmd_dat {
			pinmux = <PINMUX_GPIO86__FUNC_GPIO86>;
			slew-rate = <1>;
			output-low;
		};
	};
	mtkfb_pins_lcm_dsi_te: lcm_dsi_te {
		pins_cmd_dat {
			pinmux = <PINMUX_GPIO84__FUNC_DSI_TE>;
		};
	};
};

&dispsys_config {
	pinctrl-names =
		"lcm_rst_out1_gpio", "lcm_rst_out0_gpio",
		"mode_te_te";
	pinctrl-0 = <&mtkfb_pins_lcm_rst_out1_gpio>;
	pinctrl-1 = <&mtkfb_pins_lcm_rst_out0_gpio>;
	pinctrl-2 = <&mtkfb_pins_lcm_dsi_te>;
	status = "okay";

	helper-value = <0>, /*MTK_DRM_OPT_STAGE*/
		<1>, /*MTK_DRM_OPT_USE_CMDQ*/
		<1>, /*MTK_DRM_OPT_USE_M4U*/
		<0>, /*MTK_DRM_OPT_SODI_SUPPORT*/
		<1>, /*MTK_DRM_OPT_IDLE_MGR*/
		<0>, /*MTK_DRM_OPT_IDLEMGR_SWTCH_DECOUPLE*/
		<1>, /*MTK_DRM_OPT_IDLEMGR_BY_REPAINT*/
		<0>, /*MTK_DRM_OPT_IDLEMGR_ENTER_ULPS*/
		<0>, /*MTK_DRM_OPT_IDLEMGR_KEEP_LP11*/
		<0>, /*MTK_DRM_OPT_DYNAMIC_RDMA_GOLDEN_SETTING*/
		<1>, /*MTK_DRM_OPT_IDLEMGR_DISABLE_ROUTINE_IRQ*/
		<0>, /*MTK_DRM_OPT_MET_LOG*/
		<1>, /*MTK_DRM_OPT_USE_PQ*/
		<1>, /*MTK_DRM_OPT_ESD_CHECK_RECOVERY*/
		<1>, /*MTK_DRM_OPT_ESD_CHECK_SWITCH*/
		<1>, /*MTK_DRM_OPT_PRESENT_FENCE*/
		<0>, /*MTK_DRM_OPT_RDMA_UNDERFLOW_AEE*/
		<1>, /*MTK_DRM_OPT_DSI_UNDERRUN_AEE*/
		<1>, /*MTK_DRM_OPT_HRT*/
		<1>, /*MTK_DRM_OPT_HRT_MODE*/
		<0>, /*MTK_DRM_OPT_DELAYED_TRIGGER*/
		<1>, /*MTK_DRM_OPT_OVL_EXT_LAYER*/
		<0>, /*MTK_DRM_OPT_AOD*/
		<1>, /*MTK_DRM_OPT_RPO*/
		<0>, /*MTK_DRM_OPT_DUAL_PIPE*/
		<0>, /*MTK_DRM_OPT_DC_BY_HRT*/
		<0>, /*MTK_DRM_OPT_OVL_WCG*/
		<0>, /*MTK_DRM_OPT_OVL_SBCH*/
		<1>, /*MTK_DRM_OPT_COMMIT_NO_WAIT_VBLANK*/
		<0>, /*MTK_DRM_OPT_MET*/
		<0>, /*MTK_DRM_OPT_REG_PARSER_RAW_DUMP*/
		<0>, /*MTK_DRM_OPT_VP_PQ*/
		<0>, /*MTK_DRM_OPT_GAME_PQ*/
		<0>, /*MTK_DRM_OPT_MMPATH*/
		<0>, /*MTK_DRM_OPT_HBM*/
		<1>, /*MTK_DRM_OPT_VDS_PATH_SWITCH*/
		<0>, /*MTK_DRM_OPT_LAYER_REC*/
		<1>, /*MTK_DRM_OPT_CLEAR_LAYER*/
		<1>, /*MTK_DRM_OPT_LFR*/
		<0>; /*MTK_DRM_OPT_SF_PF*/
};

&dsi0 {
	status = "okay";
	#address-cells = <1>;
	#size-cells = <0>;
	switch_fps = <0>;
	panel10@0 {
                compatible = "oplus20611,nt36672c,tm,fhdp,dsi,vdo,dphy";
                reg = <0>;
                lcd-1p8-gpios = <&pio 136 0>;
                pm-enable-gpios = <&pio 41 0>;
                reset-gpios = <&pio 86 0>;
                bias-gpios = <&pio 137 0>,
                        <&pio 138 0>;
                pinctrl-names = "default";
                port {
                        panel_in10: endpoint {
                                remote-endpoint = <&dsi_out>;
                };
                        };
        };
 	panel11@0 {
                compatible = "jdi,nt36672c,dphy,vdo,120";
                reg = <1>;
                lcd-1p8-gpios = <&pio 136 0>;
                pm-enable-gpios = <&pio 41 0>;
                reset-gpios = <&pio 86 0>;
                bias-gpios = <&pio 137 0>,
                        <&pio 138 0>;
                pinctrl-names = "default";
                port {
                        panel_in11: endpoint {
                                remote-endpoint = <&dsi_out>;
                };
                        };
        };
	panel12@0 {
                compatible = "hx83112f,dphy,vdo";
                reg = <2>;
                pm-enable-gpios = <&pio 41 0>;
                reset-gpios = <&pio 86 0>;
                bias-gpios = <&pio 137 0>,
                        <&pio 138 0>;
                pinctrl-names = "default";
                port {
                        panel_in12: endpoint {
                                remote-endpoint = <&dsi_out>;
                };
                        };
        };
	panel13@0 {
		compatible = "oplus20095,tianma,ili7807s,dphy,vdo";
		reg = <3>;
		pm-enable-gpios = <&pio 41 0>;
		reset-gpios = <&pio 86 0>;
		bias-gpios = <&pio 137 0>,
			<&pio 138 0>;
		pinctrl-names = "default";
		port {
			panel_in13: endpoint {
				remote-endpoint = <&dsi_out>;
			};
		};
	};
	ports {
		port {
			dsi_out: endpoint {
				remote-endpoint = <&panel_in10>;
			};
		};
	};
};

&mtkfb {
	pinctrl-names = "lcd_bias_enp1_gpio", "lcd_bias_enp0_gpio",
		"lcd_bias_enn1_gpio", "lcd_bias_enn0_gpio",
		"lcm_rst_out1_gpio", "lcm_rst_out0_gpio",
		"mode_te_te";
	pinctrl-0 = <&mtkfb_pins_lcd_bias_enp1>;
	pinctrl-1 = <&mtkfb_pins_lcd_bias_enp0>;
	pinctrl-2 = <&mtkfb_pins_lcd_bias_enn1>;
	pinctrl-3 = <&mtkfb_pins_lcd_bias_enn0>;
	pinctrl-4 = <&mtkfb_pins_lcm_rst_out1_gpio>;
	pinctrl-5 = <&mtkfb_pins_lcm_rst_out0_gpio>;
	pinctrl-6 = <&mtkfb_pins_lcm_dsi_te>;
	status = "okay";
};

/* accdet start */
&accdet {
	/* accdet micbias voltage: 0x09:2.85v 0x08:2.8v 0x07,
	 * 2.7v;0x05,2.5v;0x02,1.9v
	 */
	accdet-mic-vol = <8>;
	/* accdet pwm_width, pwm_thresh, fall_delay, rise_delay
	 * debounce0, debounce1, debounce3, debounce4
	 * eint pwm_width, eint pwm_thresh
	 * eint deb(debounce0, debounce1, debounce2, debounce3), inv_debounce
	 */

        headset-mode-setting = <0x500 0x500 1 0x1f0
                                0x2000 0x800 0x2000 0x44
                                0x0 0x7
                                0x5 0x9 0x9 0xd 0xe>;
        //#else /* VENDOR_EDIT */
        /*headset-mode-setting = <0x500 0x500 1 0x1f0
         *                      0x800 0x800 0x20 0x44
         *                      0x4 0x1
         *                      0x5 0x3 0x3 0x5 0xe>;
         */
         //#endif /* VENDOR_EDIT */

	accdet-plugout-debounce = <1>;
	/*1:ACC mode, 2:low cost without in bias, 6:low cost with in bias*/
	accdet-mic-mode = <2>;
	/*0--MD_MAX--UP_MAX--DW_MAX*/
	headset-three-key-threshold = <0 82 170 306>;
	//#else /* VENDOR_EDIT */
	//headset-three-key-threshold = <0 80 220 400>;
	//#endif /* VENDOR_EDIT */
	headset-three-key-threshold-CDD = <0 121 192 600>;
	/*0--MD_MAX--VOICE_MAX--UP_MAX--DW_MAX*/
	headset-four-key-threshold = <0 58 121 192 400>;

	/* moisture HW mode config start. Enable moisture detection or not
	 * default use HW mode for moisture detection
	 */
	moisture_detect_enable = <1>;
        //#endif /* VENDOR_EDIT */
	/* select VTH to 2v and 500k, use internal resitance */
	eint_use_ext_res = <0>;
	/* enable eint detection mode, if moisture detection enable
	 * eint_detect_mode = moisture_detect_mode;otherwise, select
	 * eint_detect_mode = 4 as DEFAULT
	 */
	eint_detect_mode = <5>;
	/* enable moisture detection mode, if moisture detection enable
	 * eint_detect_mode = moisture_detect_mode
	 */
	moisture_detect_mode = <5>;
	/* select 0: 2.8V; 1: 2.4V; 2: 2V; 3: VTH=MVTH(VTH2) */
	moisture_comp_vth = <2>;
	/* vref2 voltage for different water impedance */
	moisture_comp_vref2 = <2>;
	/* moisture HW mode config end */

	/* moisture SW mode config start, use external resister or not.
	 * DEFAULT NOT NEED
	 */
	moisture_use_ext_res = <0>;
	/* moisture external resister ohm, SW mode by auxadc */
	moisture-external-r = <2000000>;
	/* moisture internal resister ohm, SW mode by auxadc */
	moisture-internal-r = <47000>;
	/* moisture of water resister ohm, SW mode by auxadc*/
	moisture-water-r = <10000>;
	/* moisture SW mode config end */
        //#endif /* VENDOR_EDIT */
	status = "okay";
};
/* accdet end */

/* IRTX GPIO Start */
&irtx_pwm {
	pinctrl-names = "irtx_gpio_led_default", "irtx_gpio_led_set";
	pinctrl-0 = <&irtx_gpio_led_default>;
	pinctrl-1 = <&irtx_gpio_led_set>;
	status = "okay";
};
&pio {
	/* IRTX GPIO Settings -Start */
	/* default: GPIO0, output, high */
	irtx_gpio_led_default:irtx_gpio_led_def@gpio57 {
		pins_cmd_dat {
			pinmux = <PINMUX_GPIO57__FUNC_GPIO57>;
			slew-rate = <1>;
			bias-disable;
			output-low;
			input-schmitt-enable = <0>;
		};
	};

	irtx_gpio_led_set:irtx_gpio_led_set@gpio57 {
		pins_cmd_dat {
			pinmux = <PINMUX_GPIO57__FUNC_PWM_3>;
			slew-rate = <1>;
			output-high;
		};
	};
}; /* IRTX GPIO Settings -End */

/* FINGERPRINT start */
//ifdef OPLUS_FEATURE_FINGERPRINT
&oplus_fp_common {
    compatible = "oplus,fp_common"; //Manufacture, and Model
    oplus,fp_gpio_num = <1>;
    oplus,fp_gpio_0 = <&pio 41 0x0>;
    pinctrl-names = "default";
    pinctrl-0 = <&gpio_id0_default>;
    goodix_optical {
        oplus,fp-id = <1>; /* fp id mapping table */
        vendor-chip = <16>; /* please refer to the struct fp_vendor_t in oplus_fp_commmon.n */
        eng-menu = "-1,-1"; /* represents SNR, inclination test item in engineer menu, and 0/1 means off/on */
        chip-name = "G_3626";  /* /proc/fp_id, will be displayed in engineer menu  */
    };
    fpc_id {
	oplus,fp-id = <0>; /* fp id mapping table */
	vendor-chip = <17>; /* please refer to the struct fp_vendor_t in oplus_fp_commmon.n */
	eng-menu = "-1,-1"; /* represents SNR, inclination test item in engineer menu, and 0/1 means off/on */
	chip-name = "F_1541";  /* /proc/fp_id, will be displayed in engineer menu  */
    };
};

&pio{
	gpio_id0_default: gpio_id0_default {
		pins_cmd_dat {
			pinmux = <PINMUX_GPIO41__FUNC_GPIO41>;
			slew-rate = <0>;
			bias-pull-up = <00>;
			input-enable;
		};
	};
};

/* fpc GPIO standardization */
&fpc_interrupt {
	pinctrl-names = "default", "fpc_cs_func";
	fpc,irq-gpio    = <&pio 7 0x00>;
	fpc,reset-gpio  = <&pio 6 0x00>;
	fpc,vdd-en = <&pio 131 0x00>;
	fpc,gpio_cs = <&pio 29 0x00>;
	pinctrl-0 = <&fpc_reset_default>,<&fpc_irq_default>,<&fpc_pwr_default>;
	pinctrl-1 = <&gpio_fpc_cs_func>;
	pw_en_gpio = <&pio 131 0x00>;
	status = "okay";
	power_source_1 {
		power-mode = <2>;
		power-name = "pw_en_gpio";
		poweron-level = <0>;
		delay-time = <0>;
	};
};

&pio {
fpc_reset_default: fpc_reset_default {
					   pins_cmd_dat {
						   pinmux = <PINMUX_GPIO6__FUNC_GPIO6>;
						   slew-rate = <1>;
						   output-low;
					   };
				   };
fpc_irq_default: fpc_irq_default {
					 pins_cmd_dat {
						 pinmux = <PINMUX_GPIO7__FUNC_GPIO7>;
						 slew-rate = <0>;
						 bias-pull-up = <00>;
					 };
				 };

fpc_pwr_default: fpc_pwr_default {
					 pins_cmd_dat {
						 pinmux = <PINMUX_GPIO131__FUNC_GPIO131>;
						 slew-rate = <1>;
						 bias-disable;
						 output-low;
					 };
				 };
gpio_fpc_cs_func: gpio_fpc_cs_func {
					 pins_cmd_dat {
						 pinmux = <PINMUX_GPIO29__FUNC_SPI5_CSB>;
						 drive-strength = <3>;
					 };
				  };
};

&goodix_fp {
	goodix,gpio_irq = <&pio 7 0x00>;
	goodix,gpio_reset = <&pio 6 0x00>;
	goodix,gpio_cs = <&pio 29 0x00>;
	pinctrl-names = "default", "gf_spi_drive_6mA", "gf_cs_func";
	pinctrl-0 = <&gpio_goodix_irq_default>, <&gpio_goodix_reset_default>;
	pinctrl-1 = <&gpio_goodix_clk_6mA>, <&gpio_goodix_mosi_6mA>, <&gpio_goodix_miso_6mA>, <&gpio_goodix_cs_6mA>;
	pinctrl-2 = <&gpio_goodix_cs_func>;
	status = "okay";
};

&spi5 {
#address-cells = <1>;
#size-cells = <0>;
status = "okay";
oplus_fp: fingerprint@0 {
		 compatible = "oplus,oplus_fp";
		 reg = <0>;
		 spi-max-frequency = <8000000>;
		 spi-id = <5>;
		 spi-irq = <39>;
		 spi-reg = <11019000>;
		 dvdd-supply = <&mt_pmic_vfp_ldo_reg>;
		 dvdd-config = <3000000 3000000 150000>;
		 power-num = <2>;
		 status = "okay";
		 power_source_1 {
			 power-mode = <1>;
			 power-name = "dvdd";
			 power-config = "dvdd-config";
			 delay-time = <0>;
		 };
	 };
};
/* 1 = ldo power, refer to oplus_fp_common.h*/
&pio{
gpio_goodix_reset_default: gpio_goodix_reset_default {
				   pins_cmd_dat {
					   pinmux = <PINMUX_GPIO6__FUNC_GPIO6>;
					   slew-rate = <1>;
					   output-low;
				   };
			   };
gpio_goodix_irq_default: gpio_goodix_irq_default {
				 pins_cmd_dat {
					 pinmux = <PINMUX_GPIO7__FUNC_GPIO7>;
					 slew-rate = <0>;
					 bias-pull-down;
				 };
			 };
gpio_goodix_clk_6mA: gpio_goodix_clk_6mA {
			     pins_cmd_dat {
				     pinmux = <PINMUX_GPIO28__FUNC_SPI5_CLK>;
				     drive-strength = <2>;
			     };
		     };
gpio_goodix_mosi_6mA: gpio_goodix_mosi_6mA {
			      pins_cmd_dat {
				      pinmux = <PINMUX_GPIO30__FUNC_SPI5_MO>;
				      drive-strength = <2>;
			      };
		      };
gpio_goodix_miso_6mA: gpio_goodix_miso_6mA {
			      pins_cmd_dat {
				      pinmux = <PINMUX_GPIO31__FUNC_SPI5_MI>;
				      drive-strength = <3>;
			      };
		      };
gpio_goodix_cs_6mA: gpio_goodix_cs_6mA {
			    pins_cmd_dat {
				    pinmux = <PINMUX_GPIO29__FUNC_SPI5_CSB>;
				    drive-strength = <2>;
			    };
		    };
gpio_goodix_cs_func: gpio_goodix_cs_func {
			     pins_cmd_dat {
				     pinmux = <PINMUX_GPIO29__FUNC_SPI5_CSB>;
				     drive-strength = <2>;
			     };
		     };
};
//#endif

&odm{
        power_helper {
                compatible = "oplus,power-helper";
        };
};

#endif
//#ifdef OPLUS_FEATURE_SWTP
&swtp {
    compatible = "mediatek, swtp-eint";
    debounce = <512000>;
};
//#endif  /* OPLUS_FEATURE_SWTP */
/*End of this file, DO NOT ADD ANYTHING HERE*/

